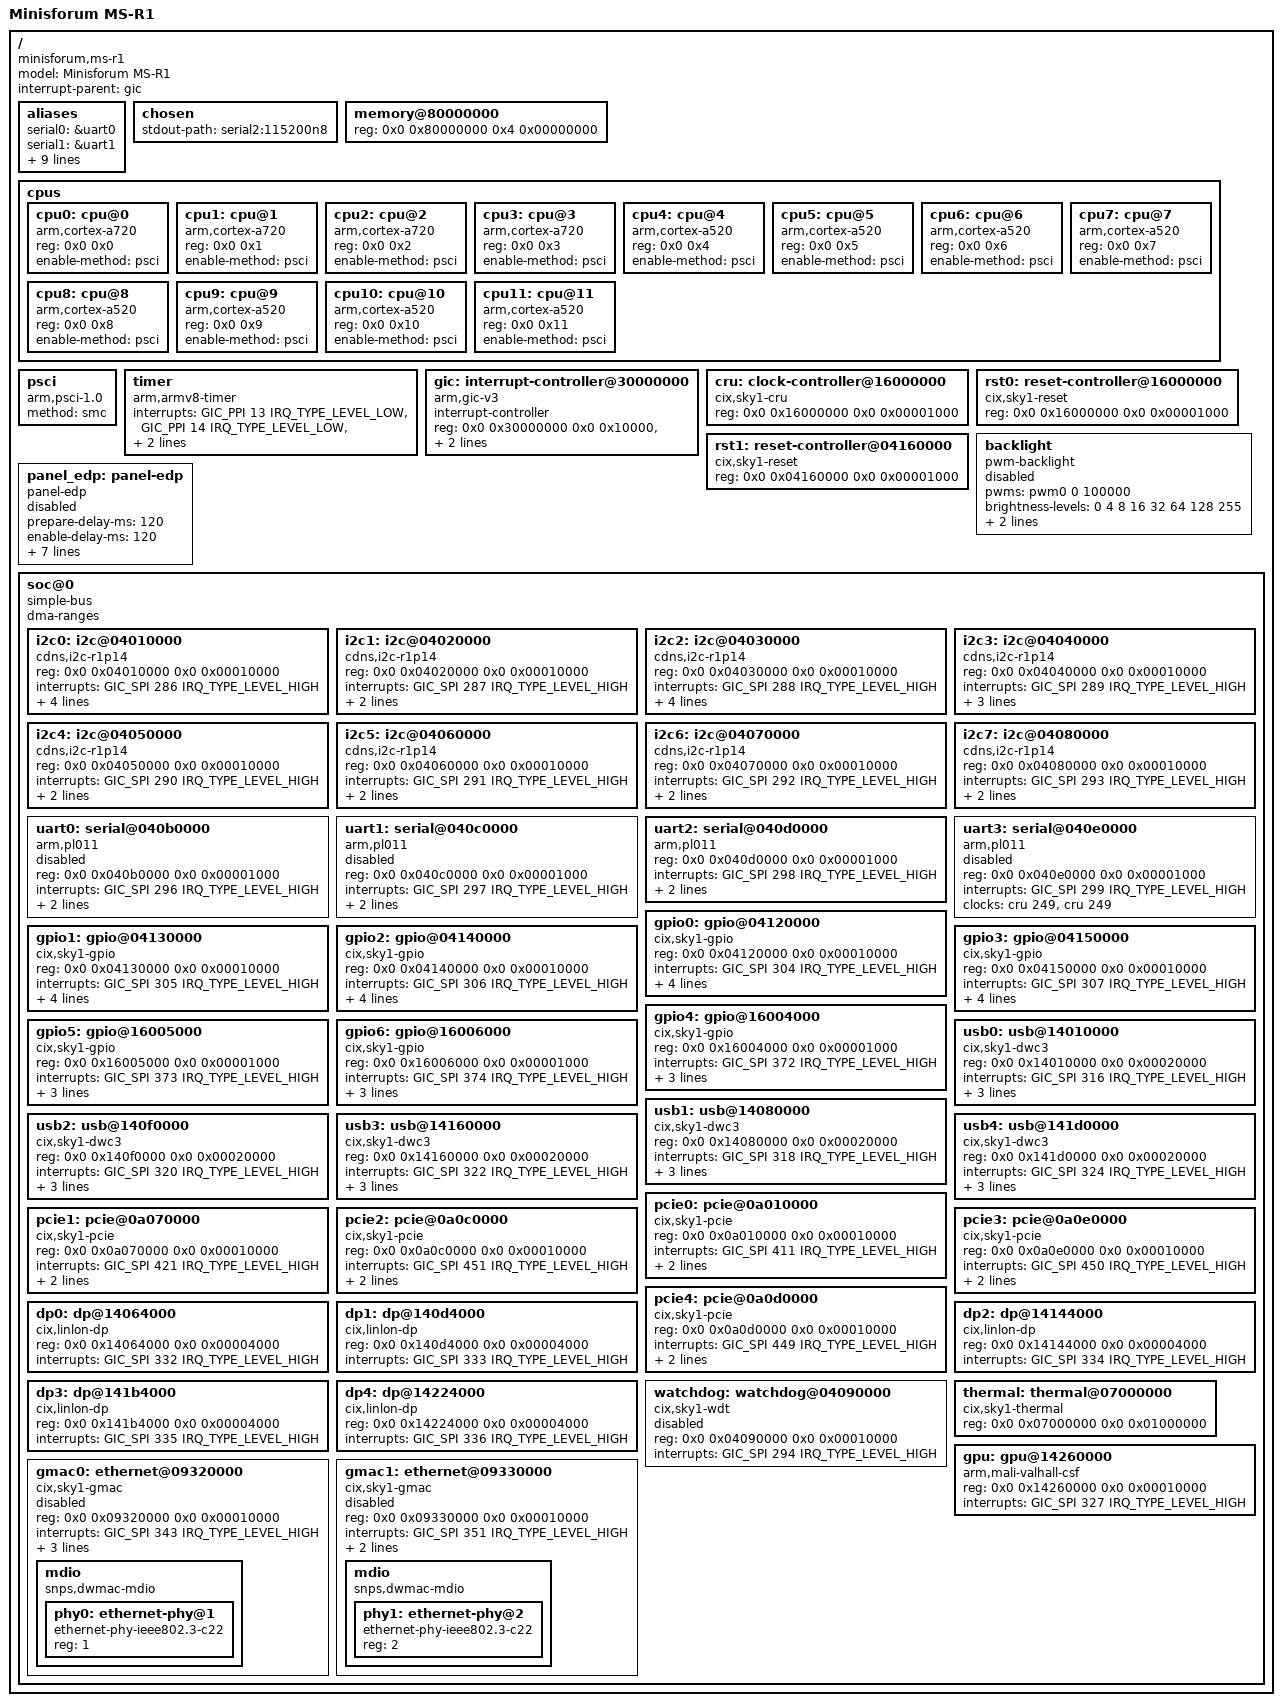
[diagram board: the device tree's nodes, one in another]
// SPDX-License-Identifier: (GPL-2.0-only OR MIT)
/*
 * Device Tree Source for Radxa Orion O6
 *
 * Auto-generated from ACPI DSDT by acpi-to-dts.sh
 * Generated: 2026-01-27T21:10:38+08:00
 *
 * This file was created from hardware extraction data.
 * Manual review and adjustment is required before use.
 *
 * Preprocessing required (from kernel source directory):
 *   cpp -nostdinc -I include -undef -x assembler-with-cpp \
 *       board.dts | dtc -I dts -O dtb -o board.dtb -
 */

/dts-v1/;

#include <dt-bindings/interrupt-controller/arm-gic.h>

/ {
	#address-cells = <2>;
	#size-cells = <2>;
	model = "Minisforum MS-R1";
	compatible = "minisforum,ms-r1", "cix,sky1";
	interrupt-parent = <&gic>;

	aliases {
		serial0 = &uart0;
		serial1 = &uart1;
		serial2 = &uart2;
		serial3 = &uart3;
		i2c0 = &i2c0;
		i2c1 = &i2c1;
		i2c2 = &i2c2;
		i2c3 = &i2c3;
		i2c4 = &i2c4;
		i2c5 = &i2c5;
		i2c6 = &i2c6;
	};

	chosen {
		stdout-path = "serial2:115200n8";
	};

	memory@80000000 {
		device_type = "memory";
		/* Memory size populated by bootloader */
		reg = <0x0 0x80000000 0x4 0x00000000>;  /* 16GB max */
	};

	cpus {
		#address-cells = <2>;
		#size-cells = <0>;

		/* CPU topology from ACPI PPTT:
		 * 4x Cortex-A720 (big cores) + 8x Cortex-A520 (little cores)
		 * big.LITTLE configuration
		 */

		cpu0: cpu@0 {
			device_type = "cpu";
			compatible = "arm,cortex-a720";
			reg = <0x0 0x0>;
			enable-method = "psci";
		};

		cpu1: cpu@1 {
			device_type = "cpu";
			compatible = "arm,cortex-a720";
			reg = <0x0 0x1>;
			enable-method = "psci";
		};

		cpu2: cpu@2 {
			device_type = "cpu";
			compatible = "arm,cortex-a720";
			reg = <0x0 0x2>;
			enable-method = "psci";
		};

		cpu3: cpu@3 {
			device_type = "cpu";
			compatible = "arm,cortex-a720";
			reg = <0x0 0x3>;
			enable-method = "psci";
		};

		cpu4: cpu@4 {
			device_type = "cpu";
			compatible = "arm,cortex-a520";
			reg = <0x0 0x4>;
			enable-method = "psci";
		};

		cpu5: cpu@5 {
			device_type = "cpu";
			compatible = "arm,cortex-a520";
			reg = <0x0 0x5>;
			enable-method = "psci";
		};

		cpu6: cpu@6 {
			device_type = "cpu";
			compatible = "arm,cortex-a520";
			reg = <0x0 0x6>;
			enable-method = "psci";
		};

		cpu7: cpu@7 {
			device_type = "cpu";
			compatible = "arm,cortex-a520";
			reg = <0x0 0x7>;
			enable-method = "psci";
		};

		cpu8: cpu@8 {
			device_type = "cpu";
			compatible = "arm,cortex-a520";
			reg = <0x0 0x8>;
			enable-method = "psci";
		};

		cpu9: cpu@9 {
			device_type = "cpu";
			compatible = "arm,cortex-a520";
			reg = <0x0 0x9>;
			enable-method = "psci";
		};

		cpu10: cpu@10 {
			device_type = "cpu";
			compatible = "arm,cortex-a520";
			reg = <0x0 0x10>;
			enable-method = "psci";
		};

		cpu11: cpu@11 {
			device_type = "cpu";
			compatible = "arm,cortex-a520";
			reg = <0x0 0x11>;
			enable-method = "psci";
		};
	};

	psci {
		compatible = "arm,psci-1.0";
		method = "smc";
	};

	timer {
		compatible = "arm,armv8-timer";
		interrupts = <GIC_PPI 13 IRQ_TYPE_LEVEL_LOW>,
			     <GIC_PPI 14 IRQ_TYPE_LEVEL_LOW>,
			     <GIC_PPI 11 IRQ_TYPE_LEVEL_LOW>,
			     <GIC_PPI 10 IRQ_TYPE_LEVEL_LOW>;
	};

	gic: interrupt-controller@30000000 {
		compatible = "arm,gic-v3";
		#interrupt-cells = <3>;
		interrupt-controller;
		reg = <0x0 0x30000000 0x0 0x10000>,  /* GICD */
		      <0x0 0x30080000 0x0 0x200000>; /* GICR */
		interrupts = <GIC_PPI 9 IRQ_TYPE_LEVEL_LOW>;
	};

	/* Clock and Reset Controllers */

	cru: clock-controller@16000000 {
		compatible = "cix,sky1-cru";
		reg = <0x0 0x16000000 0x0 0x00001000>;
		#clock-cells = <1>;
	};

	rst0: reset-controller@16000000 {
		compatible = "cix,sky1-reset";
		reg = <0x0 0x16000000 0x0 0x00001000>;
		#reset-cells = <1>;
	};

	rst1: reset-controller@04160000 {
		compatible = "cix,sky1-reset";
		reg = <0x0 0x04160000 0x0 0x00001000>;
		#reset-cells = <1>;
	};

	/* Fixed Regulators (from runtime extraction) */

	/* PWM Backlight */

	backlight: backlight {
		compatible = "pwm-backlight";
		pwms = <&pwm0 0 100000>;
		brightness-levels = <0 4 8 16 32 64 128 255>;
		default-brightness-level = <6>;
		enable-gpios = <&fch_gpio3 15 GPIO_ACTIVE_HIGH>;
		status = "disabled";
	};

	/* eDP Panel */

	panel_edp: panel-edp {
		compatible = "panel-edp";
		prepare-delay-ms = <120>;
		enable-delay-ms = <120>;
		unprepare-delay-ms = <500>;
		disable-delay-ms = <120>;
		width-mm = <129>;
		height-mm = <171>;
		enable-gpios = <&fch_gpio3 16 GPIO_ACTIVE_HIGH>;
		backlight = <&backlight>;
		pinctrl-names = "default";
		pinctrl-0 = <&pinctrl_edp0>;
		status = "disabled";
	};

	soc@0 {
		compatible = "simple-bus";
		#address-cells = <2>;
		#size-cells = <2>;
		ranges;
		dma-ranges;

		/* I2C Controllers */

		i2c0: i2c@04010000 {
			compatible = "cdns,i2c-r1p14";
			reg = <0x0 0x04010000 0x0 0x00010000>;
			interrupts = <GIC_SPI 286 IRQ_TYPE_LEVEL_HIGH>;
			clocks = <&cru 253>;
			resets = <&rst1 18>;
			reset-names = "i2c_reset";
			pinctrl-names = "default";
			pinctrl-0 = <&pinctrl_fch_i2c0>;
			#address-cells = <1>;
			#size-cells = <0>;
			clock-frequency = <400000>;
			status = "okay";
		};

		i2c1: i2c@04020000 {
			compatible = "cdns,i2c-r1p14";
			reg = <0x0 0x04020000 0x0 0x00010000>;
			interrupts = <GIC_SPI 287 IRQ_TYPE_LEVEL_HIGH>;
			clocks = <&cru 254>;
			#address-cells = <1>;
			#size-cells = <0>;
			clock-frequency = <400000>;
			status = "okay";
		};

		i2c2: i2c@04030000 {
			compatible = "cdns,i2c-r1p14";
			reg = <0x0 0x04030000 0x0 0x00010000>;
			interrupts = <GIC_SPI 288 IRQ_TYPE_LEVEL_HIGH>;
			clocks = <&cru 255>;
			resets = <&rst1 20>;
			reset-names = "i2c_reset";
			pinctrl-names = "default";
			pinctrl-0 = <&pinctrl_fch_i2c2>;
			#address-cells = <1>;
			#size-cells = <0>;
			clock-frequency = <400000>;
			status = "okay";
		};

		i2c3: i2c@04040000 {
			compatible = "cdns,i2c-r1p14";
			reg = <0x0 0x04040000 0x0 0x00010000>;
			interrupts = <GIC_SPI 289 IRQ_TYPE_LEVEL_HIGH>;
			clocks = <&cru 256>;
			pinctrl-names = "default";
			pinctrl-0 = <&pinctrl_fch_i2c3>;
			#address-cells = <1>;
			#size-cells = <0>;
			clock-frequency = <400000>;
			status = "okay";
		};

		i2c4: i2c@04050000 {
			compatible = "cdns,i2c-r1p14";
			reg = <0x0 0x04050000 0x0 0x00010000>;
			interrupts = <GIC_SPI 290 IRQ_TYPE_LEVEL_HIGH>;
			clocks = <&cru 257>;
			#address-cells = <1>;
			#size-cells = <0>;
			clock-frequency = <400000>;
			status = "okay";
		};

		i2c5: i2c@04060000 {
			compatible = "cdns,i2c-r1p14";
			reg = <0x0 0x04060000 0x0 0x00010000>;
			interrupts = <GIC_SPI 291 IRQ_TYPE_LEVEL_HIGH>;
			clocks = <&cru 258>;
			#address-cells = <1>;
			#size-cells = <0>;
			clock-frequency = <400000>;
			status = "okay";
		};

		i2c6: i2c@04070000 {
			compatible = "cdns,i2c-r1p14";
			reg = <0x0 0x04070000 0x0 0x00010000>;
			interrupts = <GIC_SPI 292 IRQ_TYPE_LEVEL_HIGH>;
			clocks = <&cru 259>;
			#address-cells = <1>;
			#size-cells = <0>;
			clock-frequency = <400000>;
			status = "okay";
		};

		i2c7: i2c@04080000 {
			compatible = "cdns,i2c-r1p14";
			reg = <0x0 0x04080000 0x0 0x00010000>;
			interrupts = <GIC_SPI 293 IRQ_TYPE_LEVEL_HIGH>;
			clocks = <&cru 260>;
			#address-cells = <1>;
			#size-cells = <0>;
			clock-frequency = <400000>;
			status = "okay";
		};

		/* UART Controllers (ARM PL011) */

		uart0: serial@040b0000 {
			compatible = "arm,pl011", "arm,primecell";
			reg = <0x0 0x040b0000 0x0 0x00001000>;
			interrupts = <GIC_SPI 296 IRQ_TYPE_LEVEL_HIGH>;
			clocks = <&cru 246>, <&cru 246>;
			clock-names = "uartclk", "apb_pclk";
			pinctrl-names = "default";
			pinctrl-0 = <&pinctrl_fch_uart0>;
			status = "disabled";
		};

		uart1: serial@040c0000 {
			compatible = "arm,pl011", "arm,primecell";
			reg = <0x0 0x040c0000 0x0 0x00001000>;
			interrupts = <GIC_SPI 297 IRQ_TYPE_LEVEL_HIGH>;
			clocks = <&cru 247>, <&cru 247>;
			clock-names = "uartclk", "apb_pclk";
			pinctrl-names = "default";
			pinctrl-0 = <&pinctrl_fch_uart1>;
			status = "disabled";
		};

		uart2: serial@040d0000 {
			compatible = "arm,pl011", "arm,primecell";
			reg = <0x0 0x040d0000 0x0 0x00001000>;
			interrupts = <GIC_SPI 298 IRQ_TYPE_LEVEL_HIGH>;
			clocks = <&cru 248>, <&cru 248>;
			clock-names = "uartclk", "apb_pclk";
			pinctrl-names = "default";
			pinctrl-0 = <&pinctrl_fch_uart2>;
			status = "okay";
		};

		uart3: serial@040e0000 {
			compatible = "arm,pl011", "arm,primecell";
			reg = <0x0 0x040e0000 0x0 0x00001000>;
			interrupts = <GIC_SPI 299 IRQ_TYPE_LEVEL_HIGH>;
			clocks = <&cru 249>, <&cru 249>;
			clock-names = "uartclk", "apb_pclk";
			status = "disabled";
		};

		/* GPIO Controllers */

		gpio0: gpio@04120000 {
			compatible = "cix,sky1-gpio";
			reg = <0x0 0x04120000 0x0 0x00010000>;
			interrupts = <GIC_SPI 304 IRQ_TYPE_LEVEL_HIGH>;
			clocks = <&cru 262>;
			resets = <&rst1 26>;
			reset-names = "apb_reset";
			gpio-controller;
			#gpio-cells = <2>;
			interrupt-controller;
			#interrupt-cells = <2>;
			status = "okay";
		};

		gpio1: gpio@04130000 {
			compatible = "cix,sky1-gpio";
			reg = <0x0 0x04130000 0x0 0x00010000>;
			interrupts = <GIC_SPI 305 IRQ_TYPE_LEVEL_HIGH>;
			clocks = <&cru 262>;
			resets = <&rst1 26>;
			reset-names = "apb_reset";
			gpio-controller;
			#gpio-cells = <2>;
			interrupt-controller;
			#interrupt-cells = <2>;
			status = "okay";
		};

		gpio2: gpio@04140000 {
			compatible = "cix,sky1-gpio";
			reg = <0x0 0x04140000 0x0 0x00010000>;
			interrupts = <GIC_SPI 306 IRQ_TYPE_LEVEL_HIGH>;
			clocks = <&cru 262>;
			resets = <&rst1 26>;
			reset-names = "apb_reset";
			gpio-controller;
			#gpio-cells = <2>;
			interrupt-controller;
			#interrupt-cells = <2>;
			status = "okay";
		};

		gpio3: gpio@04150000 {
			compatible = "cix,sky1-gpio";
			reg = <0x0 0x04150000 0x0 0x00010000>;
			interrupts = <GIC_SPI 307 IRQ_TYPE_LEVEL_HIGH>;
			clocks = <&cru 262>;
			resets = <&rst1 26>;
			reset-names = "apb_reset";
			gpio-controller;
			#gpio-cells = <2>;
			interrupt-controller;
			#interrupt-cells = <2>;
			status = "okay";
		};

		gpio4: gpio@16004000 {
			compatible = "cix,sky1-gpio";
			reg = <0x0 0x16004000 0x0 0x00001000>;
			interrupts = <GIC_SPI 372 IRQ_TYPE_LEVEL_HIGH>;
			clocks = <&cru 262>;
			gpio-controller;
			#gpio-cells = <2>;
			interrupt-controller;
			#interrupt-cells = <2>;
			status = "okay";
		};

		gpio5: gpio@16005000 {
			compatible = "cix,sky1-gpio";
			reg = <0x0 0x16005000 0x0 0x00001000>;
			interrupts = <GIC_SPI 373 IRQ_TYPE_LEVEL_HIGH>;
			clocks = <&cru 262>;
			gpio-controller;
			#gpio-cells = <2>;
			interrupt-controller;
			#interrupt-cells = <2>;
			status = "okay";
		};

		gpio6: gpio@16006000 {
			compatible = "cix,sky1-gpio";
			reg = <0x0 0x16006000 0x0 0x00001000>;
			interrupts = <GIC_SPI 374 IRQ_TYPE_LEVEL_HIGH>;
			clocks = <&cru 262>;
			gpio-controller;
			#gpio-cells = <2>;
			interrupt-controller;
			#interrupt-cells = <2>;
			status = "okay";
		};

		/* USB Controllers (Synopsys DWC3) */

		usb0: usb@14010000 {
			compatible = "cix,sky1-dwc3";
			reg = <0x0 0x14010000 0x0 0x00020000>;
			interrupts = <GIC_SPI 316 IRQ_TYPE_LEVEL_HIGH>;
			dr_mode = "host";
			snps,dis_u2_susphy_quirk;
			snps,dis_u3_susphy_quirk;
			status = "okay";
		};

		usb1: usb@14080000 {
			compatible = "cix,sky1-dwc3";
			reg = <0x0 0x14080000 0x0 0x00020000>;
			interrupts = <GIC_SPI 318 IRQ_TYPE_LEVEL_HIGH>;
			dr_mode = "host";
			snps,dis_u2_susphy_quirk;
			snps,dis_u3_susphy_quirk;
			status = "okay";
		};

		usb2: usb@140f0000 {
			compatible = "cix,sky1-dwc3";
			reg = <0x0 0x140f0000 0x0 0x00020000>;
			interrupts = <GIC_SPI 320 IRQ_TYPE_LEVEL_HIGH>;
			dr_mode = "host";
			snps,dis_u2_susphy_quirk;
			snps,dis_u3_susphy_quirk;
			status = "okay";
		};

		usb3: usb@14160000 {
			compatible = "cix,sky1-dwc3";
			reg = <0x0 0x14160000 0x0 0x00020000>;
			interrupts = <GIC_SPI 322 IRQ_TYPE_LEVEL_HIGH>;
			dr_mode = "host";
			snps,dis_u2_susphy_quirk;
			snps,dis_u3_susphy_quirk;
			status = "okay";
		};

		usb4: usb@141d0000 {
			compatible = "cix,sky1-dwc3";
			reg = <0x0 0x141d0000 0x0 0x00020000>;
			interrupts = <GIC_SPI 324 IRQ_TYPE_LEVEL_HIGH>;
			dr_mode = "host";
			snps,dis_u2_susphy_quirk;
			snps,dis_u3_susphy_quirk;
			status = "okay";
		};

		/* PCIe Controllers */

		pcie0: pcie@0a010000 {
			compatible = "cix,sky1-pcie";
			reg = <0x0 0x0a010000 0x0 0x00010000>;
			interrupts = <GIC_SPI 411 IRQ_TYPE_LEVEL_HIGH>;
			#address-cells = <3>;
			#size-cells = <2>;
			device_type = "pci";
			bus-range = <0x0 0xff>;
			num-lanes = <1>;  /* Adjust based on slot */
			status = "okay";
		};

		pcie1: pcie@0a070000 {
			compatible = "cix,sky1-pcie";
			reg = <0x0 0x0a070000 0x0 0x00010000>;
			interrupts = <GIC_SPI 421 IRQ_TYPE_LEVEL_HIGH>;
			#address-cells = <3>;
			#size-cells = <2>;
			device_type = "pci";
			bus-range = <0x0 0xff>;
			num-lanes = <1>;  /* Adjust based on slot */
			status = "okay";
		};

		pcie2: pcie@0a0c0000 {
			compatible = "cix,sky1-pcie";
			reg = <0x0 0x0a0c0000 0x0 0x00010000>;
			interrupts = <GIC_SPI 451 IRQ_TYPE_LEVEL_HIGH>;
			#address-cells = <3>;
			#size-cells = <2>;
			device_type = "pci";
			bus-range = <0x0 0xff>;
			num-lanes = <1>;  /* Adjust based on slot */
			status = "okay";
		};

		pcie3: pcie@0a0e0000 {
			compatible = "cix,sky1-pcie";
			reg = <0x0 0x0a0e0000 0x0 0x00010000>;
			interrupts = <GIC_SPI 450 IRQ_TYPE_LEVEL_HIGH>;
			#address-cells = <3>;
			#size-cells = <2>;
			device_type = "pci";
			bus-range = <0x0 0xff>;
			num-lanes = <1>;  /* Adjust based on slot */
			status = "okay";
		};

		pcie4: pcie@0a0d0000 {
			compatible = "cix,sky1-pcie";
			reg = <0x0 0x0a0d0000 0x0 0x00010000>;
			interrupts = <GIC_SPI 449 IRQ_TYPE_LEVEL_HIGH>;
			#address-cells = <3>;
			#size-cells = <2>;
			device_type = "pci";
			bus-range = <0x0 0xff>;
			num-lanes = <1>;  /* Adjust based on slot */
			status = "okay";
		};

		/* Display Controllers */

		dp0: dp@14064000 {
			compatible = "cix,linlon-dp";
			reg = <0x0 0x14064000 0x0 0x00004000>;
			interrupts = <GIC_SPI 332 IRQ_TYPE_LEVEL_HIGH>;
			status = "okay";
		};

		dp1: dp@140d4000 {
			compatible = "cix,linlon-dp";
			reg = <0x0 0x140d4000 0x0 0x00004000>;
			interrupts = <GIC_SPI 333 IRQ_TYPE_LEVEL_HIGH>;
			status = "okay";
		};

		dp2: dp@14144000 {
			compatible = "cix,linlon-dp";
			reg = <0x0 0x14144000 0x0 0x00004000>;
			interrupts = <GIC_SPI 334 IRQ_TYPE_LEVEL_HIGH>;
			status = "okay";
		};

		dp3: dp@141b4000 {
			compatible = "cix,linlon-dp";
			reg = <0x0 0x141b4000 0x0 0x00004000>;
			interrupts = <GIC_SPI 335 IRQ_TYPE_LEVEL_HIGH>;
			status = "okay";
		};

		dp4: dp@14224000 {
			compatible = "cix,linlon-dp";
			reg = <0x0 0x14224000 0x0 0x00004000>;
			interrupts = <GIC_SPI 336 IRQ_TYPE_LEVEL_HIGH>;
			status = "okay";
		};

		/* Miscellaneous Peripherals */

		watchdog: watchdog@04090000 {
			compatible = "cix,sky1-wdt";
			reg = <0x0 0x04090000 0x0 0x00010000>;
			interrupts = <GIC_SPI 294 IRQ_TYPE_LEVEL_HIGH>;
			status = "disabled";
		};

		thermal: thermal@07000000 {
			compatible = "cix,sky1-thermal";
			reg = <0x0 0x07000000 0x0 0x01000000>;
			#thermal-sensor-cells = <1>;
			status = "okay";
		};

		gpu: gpu@14260000 {
			compatible = "arm,mali-valhall-csf";
			reg = <0x0 0x14260000 0x0 0x00010000>;
			interrupts = <GIC_SPI 327 IRQ_TYPE_LEVEL_HIGH>;
			status = "okay";
		};

		gmac0: ethernet@09320000 {
			compatible = "cix,sky1-gmac";
			reg = <0x0 0x09320000 0x0 0x00010000>;
			interrupts = <GIC_SPI 343 IRQ_TYPE_LEVEL_HIGH>;
			pinctrl-names = "default";
			pinctrl-0 = <&gmac0,gmac0-init>;
			phy-mode = "rgmii-id";
			phy-handle = <&phy0>;
			status = "disabled";

			mdio {
				compatible = "snps,dwmac-mdio";
				#address-cells = <1>;
				#size-cells = <0>;

				phy0: ethernet-phy@1 {
					compatible = "ethernet-phy-ieee802.3-c22";
					reg = <1>;
				};
			};
		};

		gmac1: ethernet@09330000 {
			compatible = "cix,sky1-gmac";
			reg = <0x0 0x09330000 0x0 0x00010000>;
			interrupts = <GIC_SPI 351 IRQ_TYPE_LEVEL_HIGH>;
			phy-mode = "rgmii-id";
			phy-handle = <&phy1>;
			status = "disabled";

			mdio {
				compatible = "snps,dwmac-mdio";
				#address-cells = <1>;
				#size-cells = <0>;

				phy1: ethernet-phy@2 {
					compatible = "ethernet-phy-ieee802.3-c22";
					reg = <2>;
				};
			};
		};
	}; /* end soc@0 */

}; /* end of root node */
